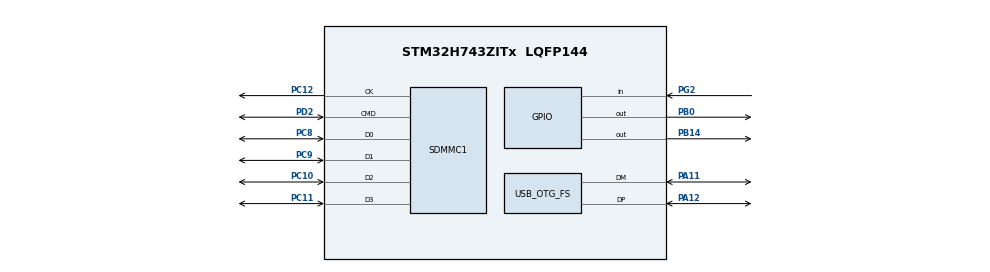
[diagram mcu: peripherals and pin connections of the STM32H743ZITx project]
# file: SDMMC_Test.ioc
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FATFS._MAX_SS=4096
Mcu.Family=STM32H7
Mcu.Name=STM32H743ZITx
Mcu.Package=LQFP144
NVIC.OTG_FS_IRQn=true\:0\:0\:false\:false\:true\:false\:true
NVIC.PriorityGroup=NVIC_PRIORITYGROUP_4
PA11.Mode=Device_Only
PA11.Signal=USB_OTG_FS_DM
PA12.Mode=Device_Only
PA12.Signal=USB_OTG_FS_DP
PB0.Signal=GPIO_Output
PB14.Signal=GPIO_Output
PC10.Mode=SD_4_bits_Wide_bus
PC10.Signal=SDMMC1_D2
PC11.Mode=SD_4_bits_Wide_bus
PC11.Signal=SDMMC1_D3
PC12.Mode=SD_4_bits_Wide_bus
PC12.Signal=SDMMC1_CK
PC8.Mode=SD_4_bits_Wide_bus
PC8.Signal=SDMMC1_D0
PC9.Mode=SD_4_bits_Wide_bus
PC9.Signal=SDMMC1_D1
PD2.Mode=SD_4_bits_Wide_bus
PD2.Signal=SDMMC1_CMD
PG2.Signal=GPIO_Input
PH0-OSC_IN\ (PH0).Mode=HSE-External-Oscillator
PH0-OSC_IN\ (PH0).Signal=RCC_OSC_IN
PH1-OSC_OUT\ (PH1).Mode=HSE-External-Oscillator
PH1-OSC_OUT\ (PH1).Signal=RCC_OSC_OUT
ProjectManager.HeapSize=0x200
ProjectManager.StackSize=0x400
ProjectManager.TargetToolchain=STM32CubeIDE
RCC.ADCFreq_Value=13500000
RCC.APB1Freq_Value=64000000
RCC.APB2Freq_Value=64000000
RCC.APB3Freq_Value=64000000
RCC.APB4Freq_Value=64000000
RCC.CortexFreq_Value=64000000
RCC.DIVM1=1
RCC.DIVM2=4
RCC.DIVN1=18
RCC.DIVN2=13
RCC.DIVQ1=75
RCC.DIVR2=3
RCC.HCLKFreq_Value=64000000
RCC.HSE_VALUE=8000000
RCC.PLL2FRACN=4096
RCC.PLL3FRACN=0
RCC.PLLFRACN=6144
RCC.PLLSourceVirtual=RCC_PLLSOURCE_HSE
RCC.SYSCLKFreq_VALUE=64000000
RCC.USBCLockSelection=RCC_USBCLKSOURCE_HSI48
RCC.USBFreq_Value=48000000
SDMMC1.ClockDiv=0
USB_DEVICE.CLASS_NAME_FS=MSC
USB_DEVICE.VirtualMode-MSC_FS=Msc
USB_DEVICE.VirtualModeFS=Msc_FS
USB_OTG_FS.VirtualMode=Device_Only
VP_FATFS_VS_SDIO.Mode=SDIO
VP_USB_DEVICE_VS_USB_DEVICE_MSC_FS.Mode=MSC_FS
board=NUCLEO-H743ZI2

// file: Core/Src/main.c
/* USER CODE BEGIN Header */
/**
  ******************************************************************************
  * @file           : main.c
  * @brief          : Main program body
  ******************************************************************************
  * @attention
  *
  * <h2><center>&copy; Copyright (c) 2020 STMicroelectronics.
  * All rights reserved.</center></h2>
  *
  * This software component is licensed by ST under BSD 3-Clause license,
  * the "License"; You may not use this file except in compliance with the
  * License. You may obtain a copy of the License at:
  *                        opensource.org/licenses/BSD-3-Clause
  *
  ******************************************************************************
  */
/* USER CODE END Header */
#include "main.h"
#include "fatfs.h"
#include "usb_device.h"

SD_HandleTypeDef hsd1;

void SystemClock_Config(void);
static void MX_GPIO_Init(void);
static void MX_SDMMC1_SD_Init(void);

/* USER CODE BEGIN 0 */
FATFS myFATAFS;
FIL myFILE;
UINT testByte;
/* USER CODE END 0 */

int main(void)
{

  /* MCU Configuration--------------------------------------------------------*/

  /* Reset of all peripherals, Initializes the Flash interface and the Systick. */
  HAL_Init();

  /* Configure the system clock */
  SystemClock_Config();

  /* Initialize all configured peripherals */
  MX_GPIO_Init();
  MX_SDMMC1_SD_Init();
  MX_FATFS_Init();
  MX_USB_DEVICE_Init();
  /* USER CODE BEGIN 2 */

  if(f_mount(&myFATAFS, SDPath, 1) == FR_OK){
	  HAL_GPIO_TogglePin(GPIOB, GPIO_PIN_0);
	  char myPath[] = "Data.csv\0";
	  f_open(&myFILE, myPath, FA_WRITE | FA_CREATE_ALWAYS);
	  char myData[] = "This is some data. This is some more data";
	  f_write(&myFILE, myData, sizeof(myData), &testByte);
	  f_close(&myFILE);
	  HAL_Delay(3000);
  }

  /* USER CODE END 2 */

  /* Infinite loop */
  /* USER CODE BEGIN WHILE */
  while (1)
  {

	  HAL_GPIO_TogglePin(GPIOB, GPIO_PIN_14);
	  HAL_Delay(1000);
    /* USER CODE END WHILE */

  }
}

void SystemClock_Config(void)
{
  RCC_OscInitTypeDef RCC_OscInitStruct = {0};
  RCC_ClkInitTypeDef RCC_ClkInitStruct = {0};
  RCC_PeriphCLKInitTypeDef PeriphClkInitStruct = {0};

  /** Supply configuration update enable
  */
  HAL_PWREx_ConfigSupply(PWR_LDO_SUPPLY);
  /** Configure the main internal regulator output voltage
  */
  __HAL_PWR_VOLTAGESCALING_CONFIG(PWR_REGULATOR_VOLTAGE_SCALE3);

  while(!__HAL_PWR_GET_FLAG(PWR_FLAG_VOSRDY)) {}
  /** Initializes the RCC Oscillators according to the specified parameters
  * in the RCC_OscInitTypeDef structure.
  */
  RCC_OscInitStruct.OscillatorType = RCC_OSCILLATORTYPE_HSI48|RCC_OSCILLATORTYPE_HSI
                              |RCC_OSCILLATORTYPE_HSE;
  RCC_OscInitStruct.HSEState = RCC_HSE_ON;
  RCC_OscInitStruct.HSIState = RCC_HSI_DIV1;
  RCC_OscInitStruct.HSICalibrationValue = RCC_HSICALIBRATION_DEFAULT;
  RCC_OscInitStruct.HSI48State = RCC_HSI48_ON;
  RCC_OscInitStruct.PLL.PLLState = RCC_PLL_ON;
  RCC_OscInitStruct.PLL.PLLSource = RCC_PLLSOURCE_HSE;
  RCC_OscInitStruct.PLL.PLLM = 1;
  RCC_OscInitStruct.PLL.PLLN = 18;
  RCC_OscInitStruct.PLL.PLLP = 2;
  RCC_OscInitStruct.PLL.PLLQ = 75;
  RCC_OscInitStruct.PLL.PLLR = 2;
  RCC_OscInitStruct.PLL.PLLRGE = RCC_PLL1VCIRANGE_3;
  RCC_OscInitStruct.PLL.PLLVCOSEL = RCC_PLL1VCOMEDIUM;
  RCC_OscInitStruct.PLL.PLLFRACN = 6144;
  if (HAL_RCC_OscConfig(&RCC_OscInitStruct) != HAL_OK)
  {
    Error_Handler();
  }
  /** Initializes the CPU, AHB and APB buses clocks
  */
  RCC_ClkInitStruct.ClockType = RCC_CLOCKTYPE_HCLK|RCC_CLOCKTYPE_SYSCLK
                              |RCC_CLOCKTYPE_PCLK1|RCC_CLOCKTYPE_PCLK2
                              |RCC_CLOCKTYPE_D3PCLK1|RCC_CLOCKTYPE_D1PCLK1;
  RCC_ClkInitStruct.SYSCLKSource = RCC_SYSCLKSOURCE_HSI;
  RCC_ClkInitStruct.SYSCLKDivider = RCC_SYSCLK_DIV1;
  RCC_ClkInitStruct.AHBCLKDivider = RCC_HCLK_DIV1;
  RCC_ClkInitStruct.APB3CLKDivider = RCC_APB3_DIV1;
  RCC_ClkInitStruct.APB1CLKDivider = RCC_APB1_DIV1;
  RCC_ClkInitStruct.APB2CLKDivider = RCC_APB2_DIV1;
  RCC_ClkInitStruct.APB4CLKDivider = RCC_APB4_DIV1;

  if (HAL_RCC_ClockConfig(&RCC_ClkInitStruct, FLASH_LATENCY_0) != HAL_OK)
  {
    Error_Handler();
  }
  PeriphClkInitStruct.PeriphClockSelection = RCC_PERIPHCLK_SDMMC|RCC_PERIPHCLK_USB;
  PeriphClkInitStruct.SdmmcClockSelection = RCC_SDMMCCLKSOURCE_PLL;
  PeriphClkInitStruct.UsbClockSelection = RCC_USBCLKSOURCE_HSI48;
  if (HAL_RCCEx_PeriphCLKConfig(&PeriphClkInitStruct) != HAL_OK)
  {
    Error_Handler();
  }
  /** Enable USB Voltage detector
  */
  HAL_PWREx_EnableUSBVoltageDetector();
}

static void MX_SDMMC1_SD_Init(void)
{

  hsd1.Instance = SDMMC1;
  hsd1.Init.ClockEdge = SDMMC_CLOCK_EDGE_RISING;
  hsd1.Init.ClockPowerSave = SDMMC_CLOCK_POWER_SAVE_DISABLE;
  hsd1.Init.BusWide = SDMMC_BUS_WIDE_4B;
  hsd1.Init.HardwareFlowControl = SDMMC_HARDWARE_FLOW_CONTROL_DISABLE;
  hsd1.Init.ClockDiv = 0;
  hsd1.Init.TranceiverPresent = SDMMC_TRANSCEIVER_NOT_PRESENT;

}

static void MX_GPIO_Init(void)
{
  GPIO_InitTypeDef GPIO_InitStruct = {0};

  /* GPIO Ports Clock Enable */
  __HAL_RCC_GPIOH_CLK_ENABLE();
  __HAL_RCC_GPIOB_CLK_ENABLE();
  __HAL_RCC_GPIOG_CLK_ENABLE();
  __HAL_RCC_GPIOC_CLK_ENABLE();
  __HAL_RCC_GPIOA_CLK_ENABLE();
  __HAL_RCC_GPIOD_CLK_ENABLE();

  /*Configure GPIO pin Output Level */
  HAL_GPIO_WritePin(GPIOB, GPIO_PIN_0|GPIO_PIN_14, GPIO_PIN_RESET);

  /*Configure GPIO pins : PB0 PB14 */
  GPIO_InitStruct.Pin = GPIO_PIN_0|GPIO_PIN_14;
  GPIO_InitStruct.Mode = GPIO_MODE_OUTPUT_PP;
  GPIO_InitStruct.Pull = GPIO_NOPULL;
  GPIO_InitStruct.Speed = GPIO_SPEED_FREQ_LOW;
  HAL_GPIO_Init(GPIOB, &GPIO_InitStruct);

  /*Configure GPIO pin : PG2 */
  GPIO_InitStruct.Pin = GPIO_PIN_2;
  GPIO_InitStruct.Mode = GPIO_MODE_INPUT;
  GPIO_InitStruct.Pull = GPIO_NOPULL;
  HAL_GPIO_Init(GPIOG, &GPIO_InitStruct);

}

void Error_Handler(void)
{
}

/************************ (C) COPYRIGHT STMicroelectronics *****END OF FILE****/
